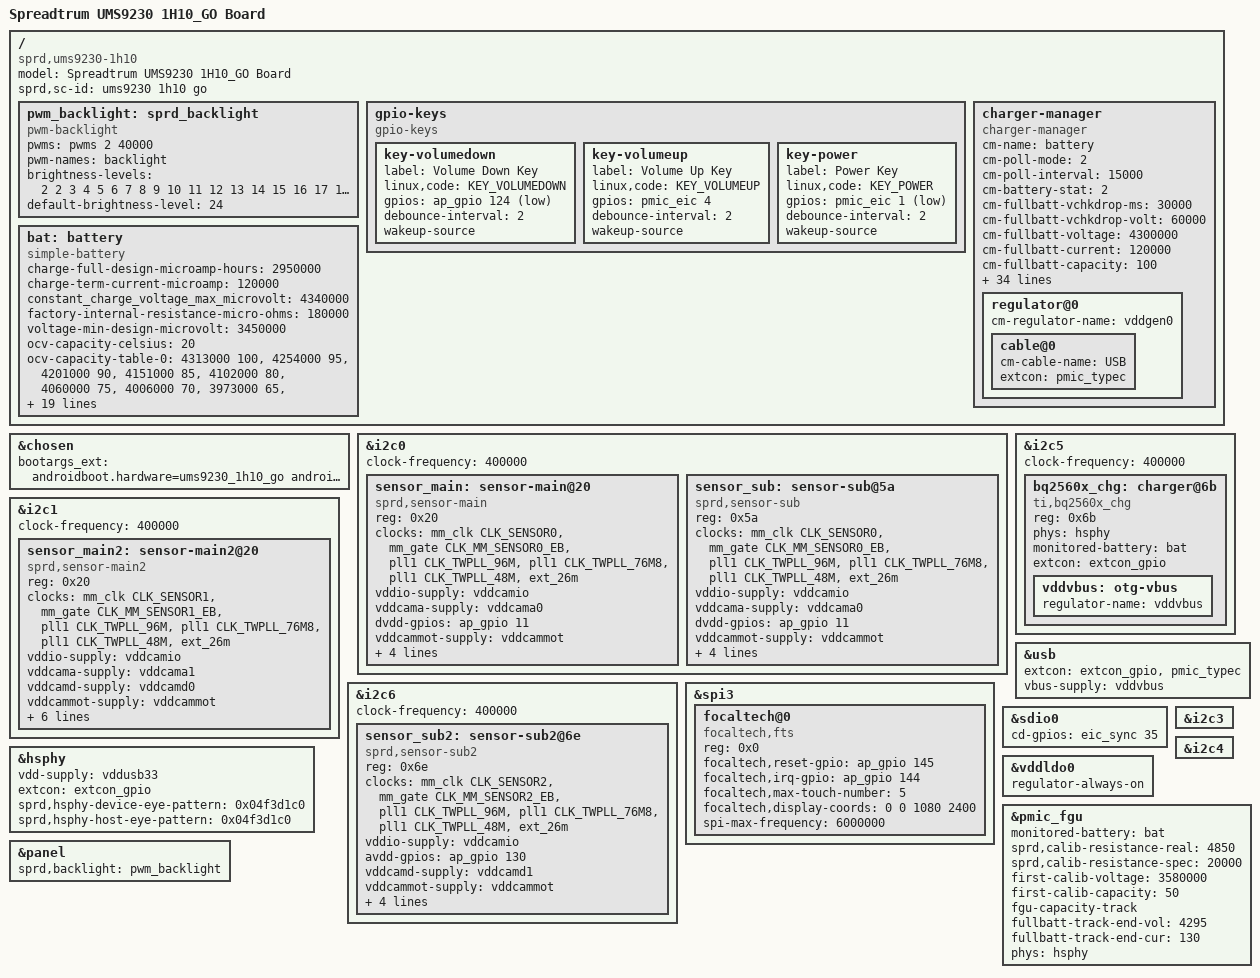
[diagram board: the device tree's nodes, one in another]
/dts-v1/;
/plugin/;
#include <dt-bindings/input/input.h>
#include <dt-bindings/gpio/gpio.h>
#include <dt-bindings/clock/sprd,ums9230-clk.h>
#include <dt-bindings/mfd/sprd,sc2730-regs.h>
#include <dt-bindings/mfd/sprd,sc2730-mask.h>
#include "lcd/lcd_g40396_truly_mipi_fhd.dtsi"

/ {

	model = "Spreadtrum UMS9230 1H10_GO Board";

	compatible = "sprd,ums9230-1h10";

	sprd,sc-id = "ums9230 1h10 go";
	fragment {
		target-path = "/";
		__overlay__ {
			pwm_backlight: sprd_backlight {
				compatible = "pwm-backlight";
				pwms = <&pwms 2 40000>;
				pwm-names = "backlight";
				brightness-levels = <
				2   2   3   4   5   6   7   8   9
				10  11  12  13  14  15  16  17  18  19
				20  21  22  23  24  25  26  27  28  29
				30  31  32  33  34  35  36  37  38  39
				40  41  42  43  44  45  46  47  48  49
				50  51  52  53  54  55  56  57  58  59
				60  61  62  63  64  65  66  67  68  69
				70  71  72  73  74  75  76  77  78  79
				80  81  82  83  84  85  86  87  88  89
				90  91  92  93  94  95  96  97  98  99
				100 101 102 103 104 105 106 107 108 109
				110 111 112 113 114 115 116 117 118 119
				120 121 122 123 124 125 126 127 128 129
				130 131 132 133 134 135 136 137 138 139
				140 141 142 143 144 145 146 147 148 149
				150 151 152 153 154 155 156 157 158 159
				160 161 162 163 164 165 166 167 168 169
				170 171 172 173 174 175 176 177 178 179
				180 181 182 183 184 185 186 187 188 189
				190 191 192 193 194 195 196 197 198 199
				200 201 202 203 204 205 206 207 208 209
				210 211 212 213 214 215 216 217 218 219
				220 221 222 223 224 225 226 227 228 229
				230 231 232 233 234 235 236 237 238 239
				240 241 242 243 244 245 246 247 247 247
				247 247 247 247 247 247 247
				>;
				default-brightness-level = <24>;
			};

			gpio-keys {
				compatible = "gpio-keys";

				key-volumedown {
					label = "Volume Down Key";
					linux,code = <KEY_VOLUMEDOWN>;
					gpios = <&ap_gpio 124 GPIO_ACTIVE_LOW>;
					debounce-interval = <2>;
					wakeup-source;
				};

				key-volumeup {
					label = "Volume Up Key";
					linux,code = <KEY_VOLUMEUP>;
					gpios = <&pmic_eic 4 GPIO_ACTIVE_HIGH>;
					debounce-interval = <2>;
					wakeup-source;
				};

				key-power {
					label = "Power Key";
					linux,code = <KEY_POWER>;
					gpios = <&pmic_eic 1 GPIO_ACTIVE_LOW>;
					debounce-interval = <2>;
					wakeup-source;
				};
			};

			bat: battery {
				compatible = "simple-battery";
				charge-full-design-microamp-hours = <2950000>;
				charge-term-current-microamp = <120000>;
				constant_charge_voltage_max_microvolt = <4340000>;
				factory-internal-resistance-micro-ohms = <180000>;
				voltage-min-design-microvolt = <3450000>;
				ocv-capacity-celsius = <20>;
				ocv-capacity-table-0 = <4313000 100>, <4254000 95>, <4201000 90>,
							<4151000 85>, <4102000 80>, <4060000 75>,
							<4006000 70>, <3973000 65>, <3930000 60>,
							<3882000 55>, <3851000 50>, <3829000 45>,
							<3810000 40>, <3795000 35>, <3781000 30>,
							<3765000 25>, <3746000 20>, <3722000 15>,
							<3694000 10>, <3682000 5>, <3400000 0>;
				voltage-temp-table = <1095000 800>, <986000 850>, <878000 900>,
							  <775000 950>, <678000 1000>, <590000 1050>,
							  <510000 1100>, <440000 1150>, <378000 1200>,
							  <324000 1250>, <278000 1300>, <238000 1350>,
							  <204000 1400>, <175000 1450>, <150000 1500>,
							  <129000 1550>, <111000 1600>, <96000 1650>;
				capacity-temp-table = <45 100>, <25 100>, <10 98>, <0 93>, <(-10) 85>, <(-20) 64>;
				resistance-temp-table = <45 77>, <25 100>, <10 546>, <0 769>, <(-10) 892>, <(-20) 923>;
				charge-sdp-current-microamp = <500000 500000>;
				charge-dcp-current-microamp = <2000000 2000000>;
				charge-cdp-current-microamp = <1500000 1500000>;
				charge-unknown-current-microamp = <500000 500000>;
			};

			charger-manager {
				compatible = "charger-manager";
				cm-name = "battery";
				cm-poll-mode = <2>;
				cm-poll-interval = <15000>;
				cm-battery-stat = <2>;

				cm-fullbatt-vchkdrop-ms = <30000>;
				cm-fullbatt-vchkdrop-volt = <60000>;
				cm-fullbatt-voltage = <4300000>;
				cm-fullbatt-current = <120000>;
				cm-fullbatt-capacity = <100>;

				cm-chargers = "bq2560x_charger";
				cm-fuel-gauge = "sc27xx-fgu";

				/* in deci centigrade */
				cm-battery-cold = <200>;
				cm-battery-cold-in-minus;
				cm-battery-hot = <800>;
				cm-battery-temp-diff = <100>;

				/* Allow charging for 6hr */
				cm-charging-max = <21600000>;
				/* recovery charging after stop charging 45min */
				cm-discharging-max = <2700000>;

				/* the interval to feed charger watchdog */
				cm-wdt-interval = <60>;

				/* drop voltage in microVolts to allow shutdown */
				cm-shutdown-voltage = <3100000>;

				/* when 99% of the time is exceeded, it will be forced to 100% */
				cm-tickle-time-out = <1500>;

				/* how much time to allow capacity change */
				cm-one-cap-time = <30>;
				/* cm-thermal-zone = "board-thmzone"; */
				/* when the safe charging voltage is exceeded, stop charging */
				cm-charge-voltage-max = <6500000>;
				/* drop voltage in microVolts to restart charging */
				cm-charge-voltage-drop = <700000>;
				cm-dcp-jeita-temp-table = <1000 1030 0 4400000>, <1150 1180 700000 4400000>,
					<1450 1420 2000000 4400000>, <1600 1570 700000 4100000>;
				cm-sdp-jeita-temp-table = <1000 1030 0 4400000>, <1150 1180 500000 4400000>,
					<1450 1420 500000 4400000>, <1600 1570 500000 4100000>;
				cm-cdp-jeita-temp-table = <1000 1030 0 4400000>, <1150 1180 700000 4400000>,
					<1450 1420 1500000 4400000>, <1600 1570 700000 4100000>;
				cm-unknown-jeita-temp-table = <1000 1030 0 4400000>, <1150 1180 500000 4400000>,
					<1450 1420 500000 4400000>, <1600 1570 500000 4100000>;

				monitored-battery = <&bat>;

				cm-cap-remap-table = <1 2 3>, <2 3 2>, <98 99 2>, <99 100 3>;

				regulator@0 {
					cm-regulator-name = "vddgen0";
					cable@0 {
						cm-cable-name = "USB";
						extcon = <&pmic_typec>;
					};
				};
			};
		};
	};
};

&chosen {
	bootargs_ext = "androidboot.hardware=ums9230_1h10_go androidboot.dtbo_idx=0";
};

&i2c0 {
	status = "okay";
	clock-frequency = <400000>;

	sensor_main: sensor-main@20 {
		compatible = "sprd,sensor-main";
		reg = <0x20>;
		clock-names = "clk_src","sensor_eb",
			"clk_96m","clk_76m8",
			"clk_48m","clk_26m";
		clocks = <&mm_clk CLK_SENSOR0>,<&mm_gate CLK_MM_SENSOR0_EB>,
				<&pll1 CLK_TWPLL_96M>,<&pll1 CLK_TWPLL_76M8>,
				<&pll1 CLK_TWPLL_48M>,<&ext_26m>;
		vddio-supply = <&vddcamio>;
		vddcama-supply = <&vddcama0>;
		dvdd-gpios = <&ap_gpio 11 0>;
		vddcammot-supply = <&vddcammot>;
		reset-gpios = <&ap_gpio 45 0>;
		power-down-gpios = <&ap_gpio 47 0>;
		sprd,phyid = <0>;
		csi = <&csi0>;
	};

	sensor_sub: sensor-sub@5a {
		compatible = "sprd,sensor-sub";
		reg = <0x5a>;
		clock-names = "clk_src","sensor_eb",
			"clk_96m","clk_76m8",
			"clk_48m","clk_26m";
		clocks = <&mm_clk CLK_SENSOR0>,<&mm_gate CLK_MM_SENSOR0_EB>,
				<&pll1 CLK_TWPLL_96M>,<&pll1 CLK_TWPLL_76M8>,
				<&pll1 CLK_TWPLL_48M>,<&ext_26m>;
		vddio-supply = <&vddcamio>;
		vddcama-supply = <&vddcama0>;
		dvdd-gpios = <&ap_gpio 11 0>;
		vddcammot-supply = <&vddcammot>;
		reset-gpios = <&ap_gpio 44 0>;
		power-down-gpios = <&ap_gpio 46 0>;
	/*	mipi-switch-en-gpios = <&ap_gpio 55 0>;*/
	/*	mipi-switch-mode-gpios = <&ap_gpio 8 0>;*/
		sprd,phyid = <2>;
		csi = <&csi0>;
	};
};

&i2c1 {
	status = "okay";
	clock-frequency = <400000>;

	sensor_main2: sensor-main2@20 {
		compatible = "sprd,sensor-main2";
		reg = <0x20>;
		clock-names = "clk_src","sensor_eb",
			"clk_96m","clk_76m8",
			"clk_48m","clk_26m";
		clocks = <&mm_clk CLK_SENSOR1>,<&mm_gate CLK_MM_SENSOR1_EB>,
				<&pll1 CLK_TWPLL_96M>,<&pll1 CLK_TWPLL_76M8>,
				<&pll1 CLK_TWPLL_48M>,<&ext_26m>;
		vddio-supply = <&vddcamio>;
		vddcama-supply = <&vddcama1>;
		vddcamd-supply = <&vddcamd0>;
		vddcammot-supply = <&vddcammot>;
		avdd-gpios = <&ap_gpio 33 0>;
		mot-gpios = <&ap_gpio 88 0>;
		reset-gpios = <&ap_gpio 41 0>;
		power-down-gpios = <&ap_gpio 40 0>;
	/*	mipi-switch-en-gpios = <&ap_gpio 55 0>;*/
	/*	mipi-switch-mode-gpios = <&ap_gpio 8 0>;*/
		sprd,phyid = <4>;
		csi = <&csi1>;
	};


};

&i2c5 {
	status = "okay";
	clock-frequency = <400000>;

	bq2560x_chg: charger@6b {
		compatible = "ti,bq2560x_chg";
		reg = <0x6b>;
		phys = <&hsphy>;
		monitored-battery = <&bat>;
		extcon = <&extcon_gpio>;
		vddvbus:otg-vbus {
			regulator-name = "vddvbus";
		};
	};
};

&i2c6 {
	status = "okay";
	clock-frequency = <400000>;

	sensor_sub2: sensor-sub2@6e {
		compatible = "sprd,sensor-sub2";
		reg = <0x6e>;
		clock-names = "clk_src","sensor_eb",
			"clk_96m","clk_76m8",
			"clk_48m","clk_26m";
		clocks = <&mm_clk CLK_SENSOR2>,<&mm_gate CLK_MM_SENSOR2_EB>,
			<&pll1 CLK_TWPLL_96M>,<&pll1 CLK_TWPLL_76M8>,
			<&pll1 CLK_TWPLL_48M>,<&ext_26m>;
		vddio-supply = <&vddcamio>;
		avdd-gpios = <&ap_gpio 130 0>;
		vddcamd-supply = <&vddcamd1>;
		vddcammot-supply = <&vddcammot>;
		mot-gpios = <&ap_gpio 112 0>;
		reset-gpios = <&ap_gpio 114 0>;
	/*	power-down-gpios = <&ap_gpio 40 0>;*/
		sprd,phyid = <3>;
		csi = <&csi2>;
	};
};

&spi3 {
	status = "okay";

	focaltech@0 {
		compatible = "focaltech,fts";
		reg = <0x0>;
		focaltech,reset-gpio = <&ap_gpio 145 GPIO_ACTIVE_HIGH>;
		focaltech,irq-gpio = <&ap_gpio 144 GPIO_ACTIVE_HIGH>;
		focaltech,max-touch-number = <5>;
		focaltech,display-coords =  <0 0 1080 2400>;
		spi-max-frequency = <6000000>;
	};
};

&hsphy {
	vdd-supply = <&vddusb33>;
	extcon = <&extcon_gpio>;
	sprd,hsphy-device-eye-pattern = <0x04f3d1c0>;
	sprd,hsphy-host-eye-pattern = <0x04f3d1c0>;
	status = "okay";
};

&usb {
	extcon = <&extcon_gpio>, <&pmic_typec>;
	vbus-supply = <&vddvbus>;
	status = "okay";
};

&sdio0 {
	cd-gpios = <&eic_sync 35 GPIO_ACTIVE_HIGH>;
};


&i2c3 {
	status = "okay";
};

&i2c4 {
	status = "okay";
};


&vddldo0 {
	regulator-always-on;
};

&pmic_fgu {
	monitored-battery = <&bat>;
	sprd,calib-resistance-real = <4850>;
	sprd,calib-resistance-spec = <20000>;
	first-calib-voltage = <3580000>;
	first-calib-capacity = <50>;
	fgu-capacity-track;
	fullbatt-track-end-vol = <4295>;
	fullbatt-track-end-cur = <130>;
	phys = <&hsphy>;
};

&panel {
	sprd,backlight = <&pwm_backlight>;
};
